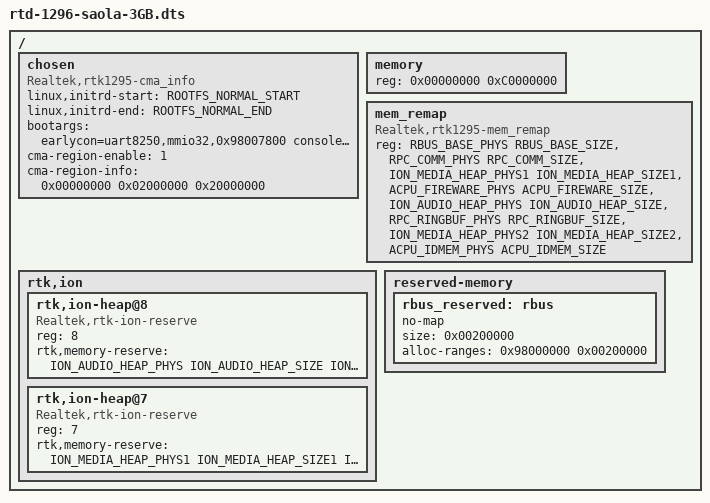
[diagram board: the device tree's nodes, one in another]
/dts-v1/;
#include "../../../../../include/soc/realtek/memory.h"

/memreserve/ SYS_BOOTCODE_MEMBASE       SYS_BOOTCODE_MEMSIZE        ; /* 0x00000000 ~ 0x00030000 */
/memreserve/ RPC_COMM_PHYS              RPC_COMM_SIZE               ; /* 0x0001f000 ~ 0x0001ffff */
/memreserve/ RESERVED_832KB_PHYS        RESERVED_832KB_SIZE         ; /* 0x00030000 ~ 0x000fffff */ 
/memreserve/ ACPU_FIREWARE_PHYS         ACPU_FIREWARE_SIZE          ; /* 0x01b00000 ~ 0x01efffff */
/memreserve/ RPC_RINGBUF_PHYS           RPC_RINGBUF_SIZE            ; /* 0x01ffe000 ~ 0x02001fff */
/memreserve/ ROOTFS_NORMAL_START        ROOTFS_NORMAL_SIZE          ; /* 0x02200000 ~ 0x025fffff */
/memreserve/ ION_AUDIO_HEAP_PHYS        ION_AUDIO_HEAP_SIZE         ; /* 0x02600000 ~ 0x031fffff */
/memreserve/ ION_MEDIA_HEAP_PHYS1       ION_MEDIA_HEAP_SIZE1        ; /* 0x03200000 ~ 0x0e9fffff */
/memreserve/ ACPU_IDMEM_PHYS            ACPU_IDMEM_SIZE             ; /* 0x10000000 ~ 0x10013fff */
/memreserve/ ION_MEDIA_HEAP_PHYS2       ION_MEDIA_HEAP_SIZE2        ; /* 0x11000000 ~ 0x1a1fffff */
/memreserve/ HW_LIMITATION_3GB_START    HW_LIMITATION_3GB_SIZE      ; /* Reserved 4KB for 3.0-GB case */
/memreserve/ HW_SECURE_RAM_START        HW_SECURE_RAM_SIZE          ; /* 32KB */
/memreserve/ HW_NOR_REMAP_START         HW_NOR_REMAP_SIZE           ; /* 32MB */


#include "rtd-1296.dtsi"
#include "rtd-129x-dvfs.dtsi"
#include "rtd-1296-saola-common.dtsi"

/ {
	chosen {
        linux,initrd-start = <ROOTFS_NORMAL_START>;
        linux,initrd-end = <ROOTFS_NORMAL_END>;
        bootargs = "earlycon=uart8250,mmio32,0x98007800 console=ttyS0,115200 init=/init androidboot.hardware=kylin androidboot.storage=emmc loglevel=4";
	};

	chosen {
        compatible = "Realtek,rtk1295-cma_info";
        /* NOTE ---------------------------------------------------------------------------------------------*/
        /* <flag size base>                                                                                  */
        /* flag: reserved                                                                                    */
        /* size: unit is byte                                                                                */
        /* base: unit is byte                                                                                */
        /* --------------------------------------------------------------------------------------------------*/
        /* Array size not over 8;                                                                            */
        /* You may change the max array size in KConfig, max CMA array size is CONFIG_CMA_AREAS+1            */
        /* If cma-region-enable is enabled<1>, kernel driver will use cma-region-info to initial CMA memory. */
        /* If cma-region-enable is disabled<0>, kernel driver will use cma= to initial CMA memory.           */
        /* if both setting is loaded, cma-region-info had higher priority.                                   */
        /* --------------------------------------------------------------------------------------------------*/
        cma-region-enable = <1>;
        cma-region-info = <0x00000000 0x02000000 0x20000000>;
        /*cma-region-info = <0x00000000 0x01000000 0x12c00000>, <0x00000000 0x12c00000 0x20000000>;*/
	};

    memory {
        device_type = "memory";
        reg = <0x00000000 0xC0000000>; /* 3072 MB */
    };

    mem_remap {
        compatible = "Realtek,rtk1295-mem_remap";
        reg = <RBUS_BASE_PHYS RBUS_BASE_SIZE>,
              <RPC_COMM_PHYS RPC_COMM_SIZE>,
              <ION_MEDIA_HEAP_PHYS1 ION_MEDIA_HEAP_SIZE1>,
              <ACPU_FIREWARE_PHYS ACPU_FIREWARE_SIZE>,
              <ION_AUDIO_HEAP_PHYS ION_AUDIO_HEAP_SIZE>,
              <RPC_RINGBUF_PHYS RPC_RINGBUF_SIZE>,
              <ION_MEDIA_HEAP_PHYS2 ION_MEDIA_HEAP_SIZE2>,
              <ACPU_IDMEM_PHYS ACPU_IDMEM_SIZE>;
    };

    rtk,ion {
        rtk,ion-heap@8 {    /* Audio */
            compatible = "Realtek,rtk-ion-reserve";
            reg = <8>;
            rtk,memory-reserve = <
                ION_AUDIO_HEAP_PHYS ION_AUDIO_HEAP_SIZE ION_AUDIO_HEAP_FLAG
                >;
        };
        rtk,ion-heap@7 {    /* TYPE_MEDIA */
            compatible = "Realtek,rtk-ion-reserve";
            reg = <7>;
            rtk,memory-reserve = <
                ION_MEDIA_HEAP_PHYS1 ION_MEDIA_HEAP_SIZE1 ION_MEDIA_HEAP_FLAG1
                ION_MEDIA_HEAP_PHYS2 ION_MEDIA_HEAP_SIZE2 ION_MEDIA_HEAP_FLAG2
                >;
        };
    };

    reserved-memory {
		#address-cells = <1>;
		#size-cells = <1>;
		ranges;

		rbus_reserved: rbus {
			no-map;
			size = <0x00200000>;
			alloc-ranges = <0x98000000 0x00200000>; 
		};
	};
};
